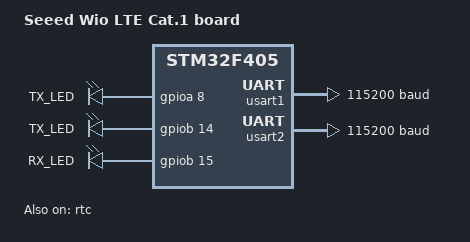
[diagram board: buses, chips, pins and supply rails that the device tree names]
/*
 * Copyright (c) 2020, Kieran Bingham <kbingham@kernel.org>
 *
 * SPDX-License-Identifier: Apache-2.0
 */

/dts-v1/;
#include <st/f4/stm32f405Xg.dtsi>

/ {
	model = "Seeed Wio LTE Cat.1 board";
	compatible = "seeed,wio-lte-cat1", "st,stm32f405";

	chosen {
		zephyr,console = &usart1;
		zephyr,shell-uart = &usart1;
		zephyr,sram = &sram0;
		zephyr,flash = &flash0;
		zephyr,code-partition = &slot0_partition;
		zephyr,ccm = &ccm0;
	};

	leds {
		compatible = "gpio-leds";

		rgb_led_pwr: ws2812b_pwr {
			gpios = <&gpioa 8 GPIO_INT_ACTIVE_HIGH>;
			label = "TX_LED";
		};

		tx_led: tx_led_1 {
			gpios = <&gpiob 14 GPIO_INT_ACTIVE_HIGH>;
			label = "TX_LED";
		};

		rx_led: rx_led_1 {
			gpios = <&gpiob 15 GPIO_INT_ACTIVE_HIGH>;
			label = "RX_LED";
		};
	};

	aliases {
		led0 = &tx_led;
		led1 = &rx_led;
	};
};

&usart1 {
	current-speed = <115200>;
	status = "okay";
};

&usart2 {
	current-speed = <115200>;
	status = "okay";
};

&rtc {
	status = "okay";
};

&flash0 {
	/*
	 * For more information, see:
	 * http://docs.zephyrproject.org/latest/guides/dts/index.html#flash-partitions
	 */
	partitions {
		compatible = "fixed-partitions";
		#address-cells = <1>;
		#size-cells = <1>;

		boot_partition: partition@0 {
			label = "mcuboot";
			reg = <0x00000000 0x00008000>;
			read-only;
		};

		/*
		 * The flash starting at offset 0x00008000 and ending at
		 * offset 0x0001ffff (sectors 2 through 4) is reserved for
		 * use by the application.
		 */

		slot0_partition: partition@20000 {
			label = "image-0";
			reg = <0x00020000 0x00020000>;
		};
		slot1_partition: partition@40000 {
			label = "image-1";
			reg = <0x00040000 0x00020000>;
		};
		scratch_partition: partition@60000 {
			label = "image-scratch";
			reg = <0x00060000 0x00020000>;
		};
	};
};

